# CH32H417 register map
Vendor: WCH Ltd.; File version: 1.2
Registers are 32-bit, read-write, reset 0x0 unless marked. A register's access mark holds for its fields unless they carry their own. Offsets are from the block's base; [hi:lo] are bit positions.

## GPHA
Base 0x40016800
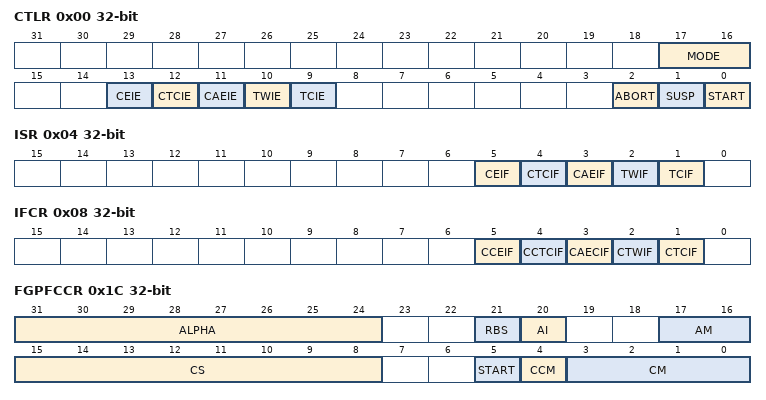
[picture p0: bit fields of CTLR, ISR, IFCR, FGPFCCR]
0x00 CTLR — GPHA control register
  [17:16] MODE — GPHA mode
  [13] CEIE — Configuration Error Interrupt Enable
  [12] CTCIE — CLUT transfer complete interrupt enable
  [11] CAEIE — CLUT access error interrupt enable
  [10] TWIE — Transfer watermark interrupt enable
  [9] TCIE — Transfer complete interrupt enable
  [2] ABORT — Abort This bit can be used to abort the current transfer.
  [1] SUSP — Suspend This bit can be used to suspend the current transfer.
  [0] START — Start This bit can be used to launch the GPHA according to the parameters loaded in the various configuration registers
0x04 ISR ro — GPHA Interrupt Status Register
  [5] CEIF — Configuration error interrupt flag
  [4] CTCIF — CLUT transfer complete interrupt flag
  [3] CAEIF — CLUT access error interrupt flag
  [2] TWIF — Transfer watermark interrupt flag
  [1] TCIF — Transfer complete interrupt flag
0x08 IFCR — GPHA interrupt flag clear register
  [5] CCEIF — Clear configuration error interrupt flag Programming
  [4] CCTCIF — Clear CLUT transfer complete interrupt flag Programming
  [3] CAECIF — Clear CLUT access error interrupt flag Programming
  [2] CTWIF — Clear transfer watermark interrupt flag Programming
  [1] CTCIF — Clear transfer complete interrupt flag Programming
0x0C FGMAR — GPHA foreground memory address register
  [31:0] MA — Memory address Address of the data used for the foreground image.
0x10 FGOR — GPHA foreground offset register
  [13:0] LO — Line offset Line offset used for the foreground expressed in pixel
0x14 BGMAR — GPHA background memory address register
  [31:0] MA — Memory address Address of the data used for the background image
0x18 BGOR — GPHA background offset register
  [13:0] LO — Line offset Line offset used for the background image (expressed in pixel)
0x1C FGPFCCR — GPHA foreground PFC control register
  [31:24] ALPHA — Alpha value
  [21] RBS — Red Blue Swap
  [20] AI — Alpha Inverted
  [17:16] AM — Alpha mode
  [15:8] CS — CLUT size
  [5] START — Start This bit can be set to start the automatic loading of the CLUT
  [4] CCM — CLUT color mode
  [3:0] CM — Color mode
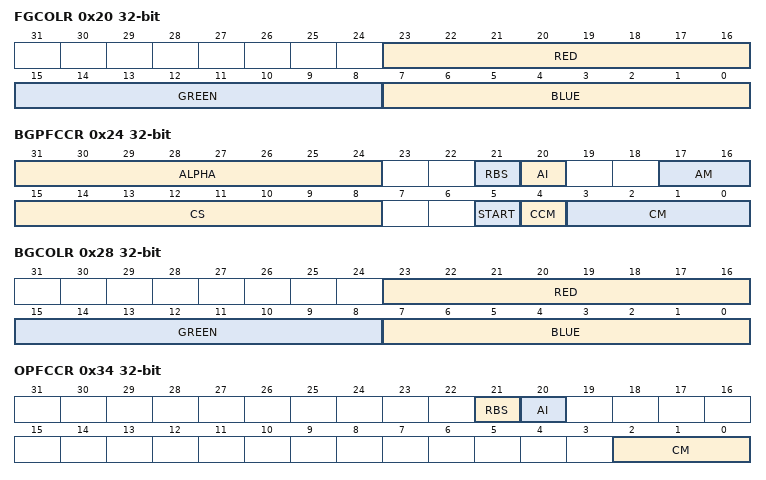
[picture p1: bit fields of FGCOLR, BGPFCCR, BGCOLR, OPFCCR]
0x20 FGCOLR — GPHA foreground color register
  [23:16] RED — Red Value These bits defines the red value for the A4 or A8 mode of the foreground image
  [15:8] GREEN — Green Value These bits defines the green value for the A4 or A8 mode of the foreground image
  [7:0] BLUE — Blue Value These bits defines the blue value for the A4 or A8 mode of the foreground image
0x24 BGPFCCR — GPHA background PFC control register
  [31:24] ALPHA — Alpha value
  [21] RBS — Red Blue Swap
  [20] AI — Alpha Inverted
  [17:16] AM — Alpha mode
  [15:8] CS — CLUT size
  [5] START — Start This bit is set to start the automatic loading of the CLUT
  [4] CCM — CLUT Color mode These bits define the color format of the CLUT
  [3:0] CM — Color mode
0x28 BGCOLR — GPHA background color register
  [23:16] RED — Red Value These bits define the red value for the A4 or A8 mode of the background
  [15:8] GREEN — Green Value These bits define the green value for the A4 or A8 mode of the background
  [7:0] BLUE — Blue Value These bits define the blue value for the A4 or A8 mode of the background
0x2C FGCMAR — GPHA foreground CLUT memory address register
  [31:0] MA — Memory Address Address of the data used for the CLUT address dedicated to the foreground image
0x30 BGCMAR — GPHA background CLUT memory address register
  [31:0] MA — Memory address Address of the data used for the CLUT address dedicated to the background image
0x34 OPFCCR — GPHA output PFC control register
  [21] RBS — Red Blue Swap
  [20] AI — Alpha Inverted This bit inverts the alpha value
  [2:0] CM — Color mode These bits define the color format of the output image
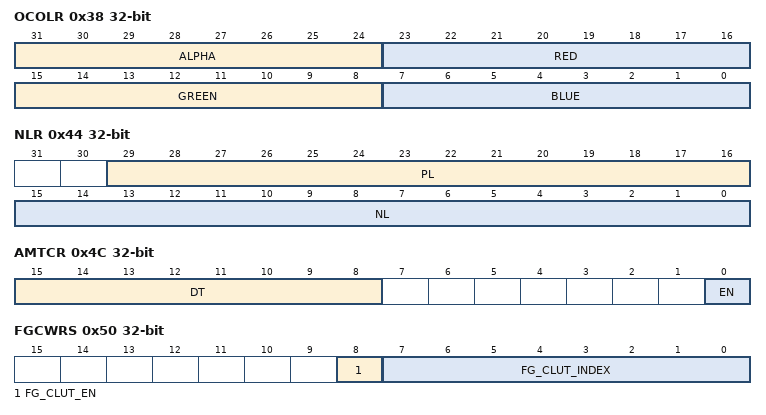
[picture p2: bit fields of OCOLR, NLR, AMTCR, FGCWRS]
0x38 OCOLR — GPHA output color register
  [31:24] ALPHA — Alpha Channel Value These bits define the alpha channel of the output color
  [23:16] RED — Red Value These bits define the red value of the output image
  [15:8] GREEN — Green Value These bits define the green value of the output image
  [7:0] BLUE — Blue Value These bits define the blue value of the output image
0x3C OMAR — GPHA output memory address register
  [31:0] MA — Memory Address Address of the data used for the output FIFO
0x40 OOR — GPHA output offset register
  [13:0] LO — Line Offset Line offset used for the output (expressed in pixels)
0x44 NLR — GPHA number of line register
  [29:16] PL — Pixel per lines Number of pixels per lines of the area to be transferred
  [15:0] NL — Number of lines Number of lines of the area to be transferred
0x48 LWR — GPHA line watermark register
  [15:0] LW — Line watermark These bits allow to configure the line watermark for interrupt generation
0x4C AMTCR — GPHA HB master timer configuration register
  [15:8] DT — Dead Time Dead time value in the HB clock cycle inserted between two consecutive accesses on the HB master port. These bits represent the minimum guaranteed number of cycles between two consecutive HB accesses.
  [0] EN — Enable Enables the dead time functionality.
0x50 FGCWRS — GPHA foreground layer CLUT read/write setting register
  [8] FG_CLUT_EN — enable CPU read/write lookup table
  [7:0] FG_CLUT_INDEX — set the address of the lookup table
0x54 FGCDAT — GPHA foreground layer CLUT read/write data register
  [31:0] FG_CLUT_DATA — read data or write SRAM data for lookup table
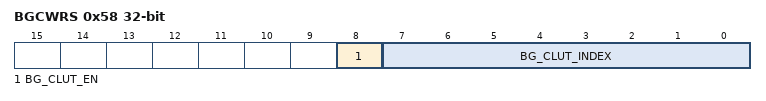
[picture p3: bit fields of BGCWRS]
0x58 BGCWRS — GPHA background layer CLUT read/write setting register
  [8] BG_CLUT_EN — enable CPU read/write lookup table
  [7:0] BG_CLUT_INDEX — set the address of the lookup table
0x5C BGCDAT — GPHA background layer CLUT read/write data register
  [31:0] BG_CLUT_DATA — read data or write SRAM data for lookup table
